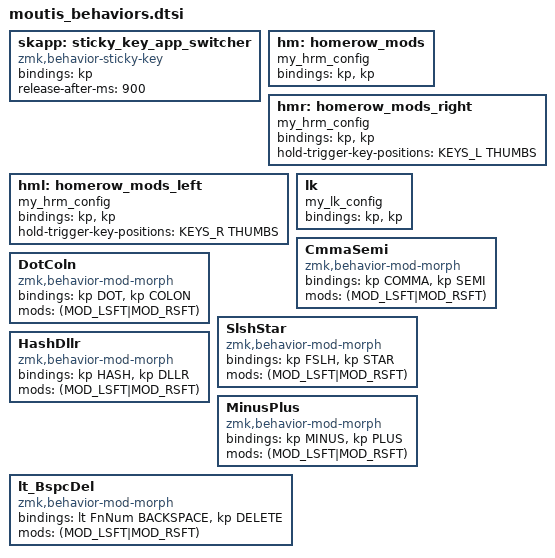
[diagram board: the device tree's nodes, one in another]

#define     my_hrm_config \
            compatible = "zmk,behavior-hold-tap"; \
            #binding-cells = <2>; \
            flavor = "balanced"; \
            hold-trigger-on-release; \
            tapping-term-ms = <my_tapping_term>; \
            quick-tap-ms = <my_quick_tapping_term>

#define     my_lt_config \
            compatible = "zmk,behavior-hold-tap"; \
            #binding-cells = <2>; \
            flavor = "tap-preferred"; \
            hold-trigger-on-release; \
            hold-while-undecided-linger; \
            tapping-term-ms = <my_tapping_term>; \
            quick-tap-ms = <my_quick_tapping_term>

#define     my_lk_config \
            compatible = "zmk,behavior-hold-tap"; \
            #binding-cells = <2>; \
            tapping-term-ms = <my_tapping_term>; \
            flavor = "tap-preferred"


        skapp: sticky_key_app_switcher {
            compatible = "zmk,behavior-sticky-key";
            #binding-cells = <1>;
            bindings = <&kp>;
            release-after-ms = <900>;
        };

        hm: homerow_mods { // use on either hand
            my_hrm_config;
            bindings = <&kp>, <&kp>;
        };
        hmr: homerow_mods_right { // use on right hand to mod left
            my_hrm_config;
            bindings = <&kp>, <&kp>;
            hold-trigger-key-positions = <KEYS_L THUMBS>; // left hand allowed
        };
        hml: homerow_mods_left { // use on left hand to mod right
            my_hrm_config;
            bindings = <&kp>, <&kp>;
            hold-trigger-key-positions = <KEYS_R THUMBS>; // right hand allowed
        };

/*
 * lk_ linger key behaviors (approximated via hold-tap)
 */
        lk: lk {
            my_lk_config;
            bindings = <&kp>, <&kp>;
        };

/*
 * modmorph behaviors
 * identified by the mixed case of each of the keycodes
 */
        CmmaSemi: CmmaSemi {
            compatible = "zmk,behavior-mod-morph";
            #binding-cells = <0>;
            bindings = <&kp COMMA>, <&kp SEMI>;
            mods = <(MOD_LSFT|MOD_RSFT)>;
        };
        DotColn: DotColn {
            compatible = "zmk,behavior-mod-morph";
            #binding-cells = <0>;
            bindings = <&kp DOT>, <&kp COLON>;
            mods = <(MOD_LSFT|MOD_RSFT)>;
        };

        SlshStar: SlshStar {
            compatible = "zmk,behavior-mod-morph";
            #binding-cells = <0>;
            bindings = <&kp FSLH>, <&kp STAR>;
            mods = <(MOD_LSFT|MOD_RSFT)>;
        };

        HashDllr: HashDllr {
            compatible = "zmk,behavior-mod-morph";
            #binding-cells = <0>;
            bindings = <&kp HASH>, <&kp DLLR>;
            mods = <(MOD_LSFT|MOD_RSFT)>;
        };
        MinusPlus: MinusPlus {
            compatible = "zmk,behavior-mod-morph";
            #binding-cells = <0>;
            bindings = <&kp MINUS>, <&kp PLUS>;
            mods = <(MOD_LSFT|MOD_RSFT)>;
        };
        lt_BspcDel: lt_BspcDel { // layer-tap mod-morph
            compatible = "zmk,behavior-mod-morph";
            #binding-cells = <0>;
            bindings = <&lt FnNum BACKSPACE>, <&kp DELETE>;
            mods = <(MOD_LSFT|MOD_RSFT)>;
        };
        
